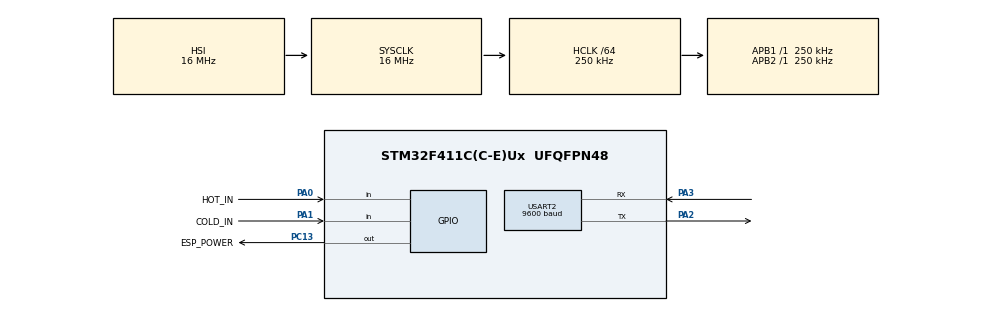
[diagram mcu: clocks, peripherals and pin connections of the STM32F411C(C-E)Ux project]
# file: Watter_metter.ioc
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Dma.Request0=USART2_TX
Dma.USART2_TX.0.Direction=DMA_MEMORY_TO_PERIPH
Dma.USART2_TX.0.FIFOMode=DMA_FIFOMODE_DISABLE
Dma.USART2_TX.0.Instance=DMA1_Stream6
Dma.USART2_TX.0.MemDataAlignment=DMA_MDATAALIGN_BYTE
Dma.USART2_TX.0.MemInc=DMA_MINC_ENABLE
Dma.USART2_TX.0.Mode=DMA_NORMAL
Dma.USART2_TX.0.PeriphDataAlignment=DMA_PDATAALIGN_BYTE
Dma.USART2_TX.0.PeriphInc=DMA_PINC_DISABLE
Dma.USART2_TX.0.Priority=DMA_PRIORITY_LOW
Mcu.Family=STM32F4
Mcu.Name=STM32F411C(C-E)Ux
Mcu.Package=UFQFPN48
NVIC.DMA1_Stream6_IRQn=true\:3\:0\:true\:false\:true\:false\:true\:true
NVIC.PriorityGroup=NVIC_PRIORITYGROUP_4
NVIC.RTC_Alarm_IRQn=true\:0\:0\:false\:false\:true\:true\:true\:true
NVIC.USART2_IRQn=true\:3\:0\:true\:false\:true\:true\:true\:true
PA0-WKUP.GPIO_Label=HOT_IN
PA0-WKUP.GPIO_PuPd=GPIO_PULLUP
PA0-WKUP.Signal=GPIO_Input
PA1.GPIO_Label=COLD_IN
PA1.GPIO_PuPd=GPIO_PULLUP
PA1.Signal=GPIO_Input
PA13.Mode=Serial_Wire
PA13.Signal=SYS_JTMS-SWDIO
PA14.Mode=Serial_Wire
PA14.Signal=SYS_JTCK-SWCLK
PA2.Mode=Asynchronous
PA2.Signal=USART2_TX
PA3.Mode=Asynchronous
PA3.Signal=USART2_RX
PC13-ANTI_TAMP.GPIO_Label=ESP_POWER
PC13-ANTI_TAMP.Signal=GPIO_Output
PC14-OSC32_IN.Mode=LSE-External-Oscillator
PC14-OSC32_IN.Signal=RCC_OSC32_IN
PC15-OSC32_OUT.Mode=LSE-External-Oscillator
PC15-OSC32_OUT.Signal=RCC_OSC32_OUT
PH0\ -\ OSC_IN.Mode=HSE-External-Oscillator
PH0\ -\ OSC_IN.Signal=RCC_OSC_IN
PH1\ -\ OSC_OUT.Mode=HSE-External-Oscillator
PH1\ -\ OSC_OUT.Signal=RCC_OSC_OUT
ProjectManager.HeapSize=0x200
ProjectManager.StackSize=0x400
ProjectManager.TargetToolchain=MDK-ARM V5.32
RCC.48MHZClocksFreq_Value=32000000
RCC.AHBCLKDivider=RCC_SYSCLK_DIV64
RCC.AHBFreq_Value=250000
RCC.APB1Freq_Value=250000
RCC.APB1TimFreq_Value=250000
RCC.APB2Freq_Value=250000
RCC.APB2TimFreq_Value=250000
RCC.CortexFreq_Value=250000
RCC.HCLKFreq_Value=250000
RCC.HSE_VALUE=25000000
RCC.HSI_VALUE=16000000
RCC.PLLM=25
RCC.PLLN=128
RCC.PLLSourceVirtual=RCC_PLLSOURCE_HSE
RCC.SYSCLKFreq_VALUE=16000000
RCC.VCOOutputFreq_Value=128000000
RTC.Alarm=RTC_ALARM_A
RTC.Format=RTC_FORMAT_BIN
RTC.Hours=0
RTC.Minutes=0
RTC.Seconds=0
RTC.Seconds_A=5
RTC.Year=24
USART2.BaudRate=9600
USART2.VirtualMode=VM_ASYNC
VP_RTC_VS_RTC_Activate.Mode=RTC_Enabled
VP_RTC_VS_RTC_Alarm_A_Intern.Mode=Alarm A
VP_RTC_VS_RTC_Calendar.Mode=RTC_Calendar
board=custom

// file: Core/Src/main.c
/* USER CODE BEGIN Header */
/**
  ******************************************************************************
  * @file           : main.c
  * @brief          : Main program body
  ******************************************************************************
  * @attention
  *
  * Copyright (c) 2024 STMicroelectronics.
  * All rights reserved.
  *
  * This software is licensed under terms that can be found in the LICENSE file
  * in the root directory of this software component.
  * If no LICENSE file comes with this software, it is provided AS-IS.
  *
  ******************************************************************************
  */
/* USER CODE END Header */
#include "main.h"
#include "dma.h"
#include "rtc.h"
#include "usart.h"
#include "gpio.h"

/* USER CODE BEGIN Includes */
//#include <stdbool.h>
//#include <string.h>
//#include <stdio.h>
/* USER CODE END Includes */

/* USER CODE BEGIN PV */
watter_type watter;
void InitAll(void);
/* USER CODE END PV */

void SystemClock_Config(void);
/* USER CODE BEGIN PFP */

void Processing(void);

/* USER CODE END PFP */

int main(void)
{

  /* MCU Configuration--------------------------------------------------------*/

  /* Reset of all peripherals, Initializes the Flash interface and the Systick. */
  HAL_Init();

  /* Configure the system clock */
  SystemClock_Config();

  /* Initialize all configured peripherals */
  MX_GPIO_Init();
  MX_DMA_Init();
  MX_RTC_Init();
  MX_USART2_UART_Init();
  /* USER CODE BEGIN 2 */
	InitAll();

  /* USER CODE END 2 */

  /* Infinite loop */
  while (1)
  {

    /* USER CODE BEGIN 3 */
		Processing();
  }
  /* USER CODE END 3 */
}

void SystemClock_Config(void)
{
  RCC_OscInitTypeDef RCC_OscInitStruct = {0};
  RCC_ClkInitTypeDef RCC_ClkInitStruct = {0};

  /** Configure the main internal regulator output voltage
  */
  __HAL_RCC_PWR_CLK_ENABLE();
  __HAL_PWR_VOLTAGESCALING_CONFIG(PWR_REGULATOR_VOLTAGE_SCALE1);

  /** Initializes the RCC Oscillators according to the specified parameters
  * in the RCC_OscInitTypeDef structure.
  */
  RCC_OscInitStruct.OscillatorType = RCC_OSCILLATORTYPE_HSI|RCC_OSCILLATORTYPE_LSI;
  RCC_OscInitStruct.HSIState = RCC_HSI_ON;
  RCC_OscInitStruct.HSICalibrationValue = RCC_HSICALIBRATION_DEFAULT;
  RCC_OscInitStruct.LSIState = RCC_LSI_ON;
  RCC_OscInitStruct.PLL.PLLState = RCC_PLL_NONE;
  if (HAL_RCC_OscConfig(&RCC_OscInitStruct) != HAL_OK)
  {
    Error_Handler();
  }

  /** Initializes the CPU, AHB and APB buses clocks
  */
  RCC_ClkInitStruct.ClockType = RCC_CLOCKTYPE_HCLK|RCC_CLOCKTYPE_SYSCLK
                              |RCC_CLOCKTYPE_PCLK1|RCC_CLOCKTYPE_PCLK2;
  RCC_ClkInitStruct.SYSCLKSource = RCC_SYSCLKSOURCE_HSI;
  RCC_ClkInitStruct.AHBCLKDivider = RCC_SYSCLK_DIV64;
  RCC_ClkInitStruct.APB1CLKDivider = RCC_HCLK_DIV1;
  RCC_ClkInitStruct.APB2CLKDivider = RCC_HCLK_DIV1;

  if (HAL_RCC_ClockConfig(&RCC_ClkInitStruct, FLASH_LATENCY_0) != HAL_OK)
  {
    Error_Handler();
  }
}

/* USER CODE BEGIN 4 */
//====================================
//====================================
/* USER CODE END 4 */

void Error_Handler(void)
{
  __disable_irq();
  while (1)
  {
  }
}
